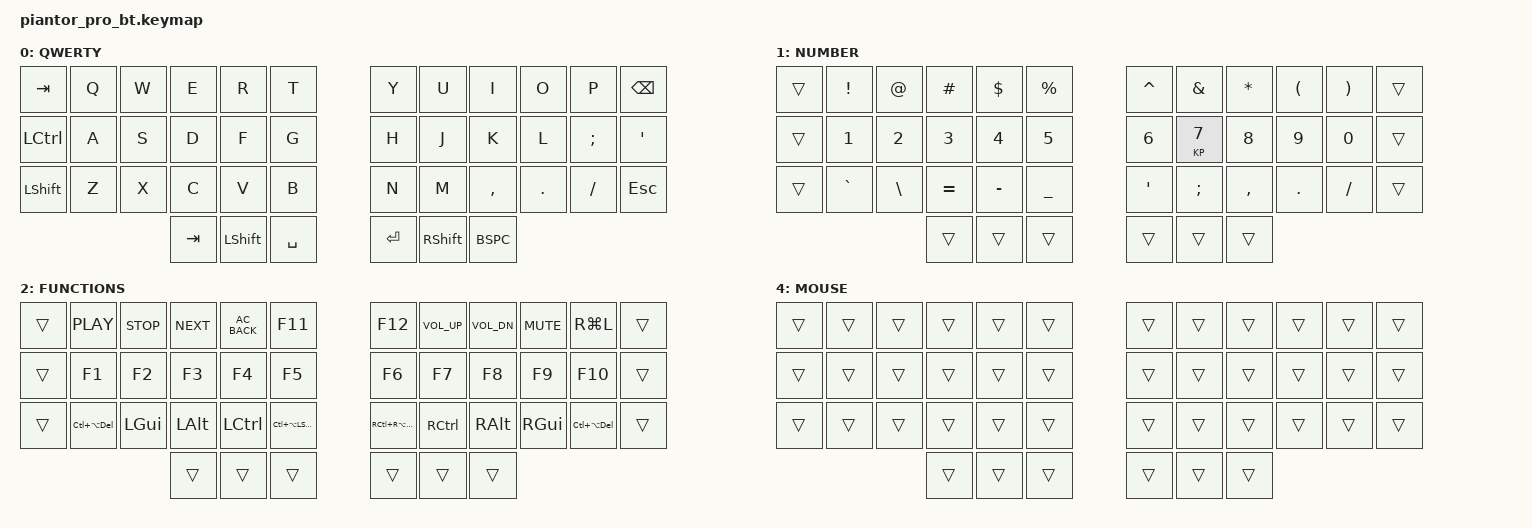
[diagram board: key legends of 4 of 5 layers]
/*
 * Copyright (c) 2020 The ZMK Contributors
 *
 * SPDX-License-Identifier: MIT
 */

#include <behaviors.dtsi>
#include <dt-bindings/zmk/keys.h>
#include <dt-bindings/zmk/bt.h>
#include <dt-bindings/zmk/rgb.h>

/ {
    chosen {
        zmk,physical-layout = &default_layout;
    };
};

/ {
    keymap {
        compatible = "zmk,keymap";

        alpha_layer  {
            display-name = "QWERTY";
            // --------------------------------------------------------------------------------
            // |  TAB |  Q  |  W  |  E  |  R  |  T  |  Y  |  U   |  I  |  O  |  P  | BSPC |
            // | CTRL |  A  |  S  |  D  |  F  |  G  |  H  |  J   |  K  |  L  |  ;  |  '   |
            // | SHFT |  Z  |  X  |  C  |  V  |  B  |  N  |  M   |  ,  |  .  |  /  | ESC  |
            //                    | GUI | LWR | SPC | ENT | RSE  | ALT |
            bindings = <
                &kp TAB   &kp Q &kp W &kp E &kp R &kp T &kp Y &kp U  &kp I     &kp O   &kp P    &kp BSPC
                &kp LCTRL &kp A &kp S &kp D &kp F &kp G &kp H &kp J  &kp K     &kp L   &kp SEMI &kp SQT
                &kp LSHFT &kp Z &kp X &kp C &kp V &kp B &kp N &kp M  &kp COMMA &kp DOT &kp FSLH &kp ESC
                               &kp TAB &kp LSHFT &kp SPACE &kp RET &kp RSHFT BSPC
            >;
        };

        numbsym_layer  {
            display-name = "NUMBER";
            // -----------------------------------------------------------------------------------------
            // |  TAB |  1  |  2  |  3  |  4  |  5    |  6  |  7  |  8  |  9  |  0  | BSPC |
            // | CTRL | BT1 | BT2 | BT3 | BT4 | BT5   | LFT | DWN |  UP | RGT |     |      |
            // | SHFT | BTCR| RGB | RST | BOOT| Unlock|     |     |     |     |     |      |
            //                    | GUI |     | SPC   | ENT |     | ALT |
            bindings = <
                &trans  &kp EXCL   &kp AT     &kp HASH   &kp DLLR   &kp PRCNT     &kp CARET  &kp AMPS    &kp ASTRK  &kp LPAR   &kp RPAR  &trans
                &trans  &kp N1     &kp N2     &kp N3     &kp N4     &kp N5        &kp N6     &KP N7      &kp N8     &kp N9     &kp N0    &trans
                &trans  &kp GRAVE  &kp BSLH   &kp EQUAL  &kp MINUS  &kp UNDER     &kp SQT    &kp SEMI    &kp COMMA  &kp DOT    &kp SLASH &trans
                                                       &trans     &trans       &trans   &trans  &trans  &trans
            >;
        };

        function_layer  {
            display-name = "FUNCTIONS";
            bindings = <
              &trans &kp C_PLAY      &kp C_STOP &kp C_NEXT &kp C_AC_BACK  &kp F11              &kp F12             &kp K_VOL_UP &kp C_VOL_DN  &kp C_MUTE  &kp RG(L)       &trans
              &trans &kp F1          &kp F2     &kp F3     &kp F4         &kp F5               &kp F6              &kp F7       &kp F8        &kp F9      &kp F10         &trans
              &trans &kp LC(LA(DEL)) &kp LGUI   &kp LALT   &kp LCTRL      &kp LC(LA(LSHIFT))   &kp RC(RA(RSHIFT))  &kp RCTRL    &kp RALT      &kp RGUI    &kp LC(LA(DEL)) &trans
                                                &trans     &trans         &trans               &trans              &trans       &trans       
            >;
        };

        appcontrol_layer  {
            display-name = "APPCONTROL";
            bindings = <
                &trans &bt BT_CLR  &bt BT_SEL 0 &kp LG(DOT)     &kp LG(R)              &kp LS(LC(LA(LG(T))))    &kp LS(LC(LA(LG(P)))) &kp C_BRI_UP    &kp C_BRI_DN          &bt BT_SEL 0 &bt BT_CLR  &trans 
                &trans &bootloader &bt BT_SEL 1 &control_panel  &kp LG(E)              &kp LS(LC(LA(LG(W))))    &kp C_AL_CALC         &kp RC(RS(ESC)) &kp LS(LC(LA(LG(L)))) &bt BT_SEL 1 &bootloader &trans 
                &trans &sys_reset  &bt BT_SEL 2 &kp LG(V)       &kp LS(LC(LA(LG(O))))  &kp LS(LC(LA(LG(X))))    &kp LS(LG(S))         &trans          &trans                &bt BT_SEL 2 &sys_reset  &trans 
                                     &trans &trans &trans  &trans &trans &trans       
            >;
        };

        mouse_layer  {
            display-name = "MOUSE";
            bindings = <
                &trans &trans &trans &trans &trans &trans  &trans &trans &trans &trans &trans &trans
                &trans &trans &trans &trans &trans &trans  &trans &trans &trans &trans &trans &trans
                &trans &trans &trans &trans &trans &trans  &trans &trans &trans &trans &trans &trans
                                     &trans &trans &trans  &trans &trans &trans       
            >;
        };

    };
};
